# SYNCTIMER register map
Vendor: Texas Instruments
Peripheral module from a debugger description file (folder am437x).
Registers are 32-bit, read-only, no defined reset value unless marked. A register's access mark holds for its fields unless they carry their own. Offsets are as the file gives them; lines under a group give offsets from that group; [hi:lo] are bit positions; {n}, {i} and the like mark numbered series; 'fields as' and 'values as' point back to an identical list; <NAME> marks a mode.

## SYNCTIMER
0x00 SYNCTIMER32K_SYNCNT_REV
  [7:0] CID_REV — Revision number.
0x04 SYNCTIMER32K_SYSCONFIG rw
  [4:3] IDLEMODE — Power Management Req/Ack Control.
    3=en_4_0x3 (Reserved.); 2=en_3_0x2 (Reserved.); 1=en_2_0x1 (No-idle. An idle request is never acknowledged.); 0=en_1_0x0 (Force idle. An idle request is acknowledged unconditionally.)
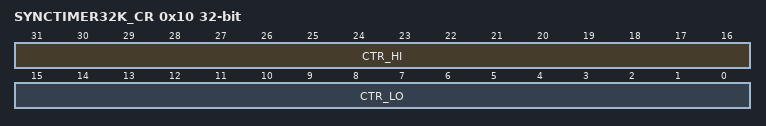
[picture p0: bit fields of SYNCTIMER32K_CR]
0x10 SYNCTIMER32K_CR
  [31:16] CTR_HI — Read counter high. [[br]]Value of [[br]]32-kHz SYNCH counter (16 bit LSB).
  [15:0] CTR_LO — Read counter low. [[br]]Value of [[br]]32-kHz SYNCH counter (16 bit MSB).
